AUTOSAR XML (schema 00046)
package /ComponentTypes
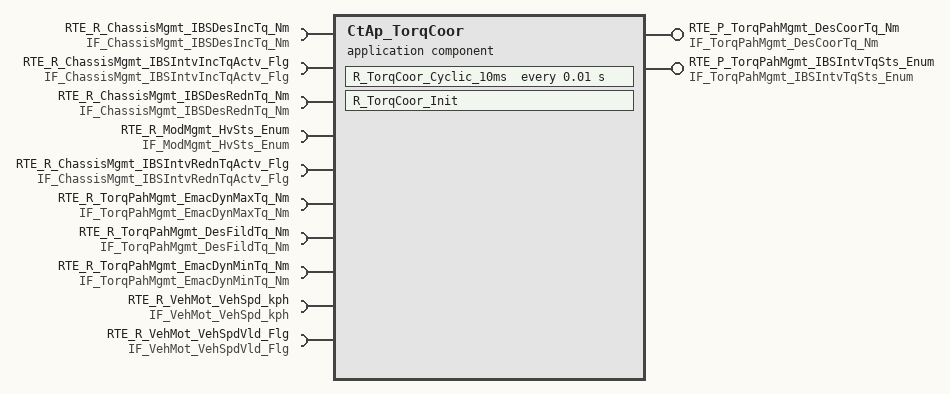
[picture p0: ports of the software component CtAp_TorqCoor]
  application sw component type CtAp_TorqCoor
    provide port RTE_P_TorqPahMgmt_DesCoorTq_Nm: nonqueued-sender-com-spec{data-element=tec_TorqPahMgmt_DesCoorTq_Nm, init-value=0}, provided-interface=IF_TorqPahMgmt_DesCoorTq_Nm
    provide port RTE_P_TorqPahMgmt_IBSIntvTqSts_Enum: nonqueued-sender-com-spec{data-element=tec_TorqPahMgmt_IBSIntvTqSts_Enum, init-value=0}, provided-interface=IF_TorqPahMgmt_IBSIntvTqSts_Enum
    10 x require port:
      RTE_R_ChassisMgmt_IBSDesIncTq_Nm: nonqueued-receiver-com-spec{data-element=tec_ChassisMgmt_IBSDesIncTq_Nm, filter=data-filter-type=ALWAYS, init-value=0}, required-interface=IF_ChassisMgmt_IBSDesIncTq_Nm
      RTE_R_ChassisMgmt_IBSIntvIncTqActv_Flg: nonqueued-receiver-com-spec{data-element=tec_ChassisMgmt_IBSIntvIncTqActv_Flg, filter=data-filter-type=ALWAYS, init-value=0}, required-interface=IF_ChassisMgmt_IBSIntvIncTqActv_Flg
      RTE_R_ChassisMgmt_IBSDesRednTq_Nm: nonqueued-receiver-com-spec{data-element=tec_ChassisMgmt_IBSDesRednTq_Nm, filter=data-filter-type=ALWAYS, init-value=0}, required-interface=IF_ChassisMgmt_IBSDesRednTq_Nm
      RTE_R_ModMgmt_HvSts_Enum: nonqueued-receiver-com-spec{data-element=tec_ModMgmt_HvSts_Enum, filter=data-filter-type=ALWAYS, init-value=0}, required-interface=IF_ModMgmt_HvSts_Enum
      RTE_R_ChassisMgmt_IBSIntvRednTqActv_Flg: nonqueued-receiver-com-spec{data-element=tec_ChassisMgmt_IBSIntvRednTqActv_Flg, filter=data-filter-type=ALWAYS, init-value=0}, required-interface=IF_ChassisMgmt_IBSIntvRednTqActv_Flg
      RTE_R_TorqPahMgmt_EmacDynMaxTq_Nm: nonqueued-receiver-com-spec{data-element=tec_TorqPahMgmt_EmacDynMaxTq_Nm, filter=data-filter-type=ALWAYS, init-value=0}, required-interface=IF_TorqPahMgmt_EmacDynMaxTq_Nm
      RTE_R_TorqPahMgmt_DesFildTq_Nm: nonqueued-receiver-com-spec{data-element=tec_TorqPahMgmt_DesFildTq_Nm, filter=data-filter-type=ALWAYS, init-value=0}, required-interface=IF_TorqPahMgmt_DesFildTq_Nm
      RTE_R_TorqPahMgmt_EmacDynMinTq_Nm: nonqueued-receiver-com-spec{data-element=tec_TorqPahMgmt_EmacDynMinTq_Nm, filter=data-filter-type=ALWAYS, init-value=0}, required-interface=IF_TorqPahMgmt_EmacDynMinTq_Nm
      RTE_R_VehMot_VehSpd_kph: nonqueued-receiver-com-spec{data-element=tec_VehMot_VehSpd_kph, filter=data-filter-type=ALWAYS, init-value=0}, required-interface=IF_VehMot_VehSpd_kph
      RTE_R_VehMot_VehSpdVld_Flg: nonqueued-receiver-com-spec{data-element=tec_VehMot_VehSpdVld_Flg, filter=data-filter-type=ALWAYS, init-value=0}, required-interface=IF_VehMot_VehSpdVld_Flg
    behavior CtAp_TorqCoor_InternalBehavior
      init event CtAp_TorqCoor_InitEvent: start-on-event=R_TorqCoor_Init
      timing event TMT_R_TorqCoor_Cyclic_10ms: start-on-event=R_TorqCoor_Cyclic_10ms, period=0.01
      runnable R_TorqCoor_Init
      runnable R_TorqCoor_Cyclic_10ms
        data-receive-point-by-arguments:
          10 x access:
            REC_RTE_R_ChassisMgmt_IBSDesIncTq_Nm_tec_ChassisMgmt_IBSDesIncTq_Nm: accessed-variable=RTE_R_ChassisMgmt_IBSDesIncTq_Nm.tec_ChassisMgmt_IBSDesIncTq_Nm
            REC_RTE_R_ChassisMgmt_IBSDesRednTq_Nm_tec_ChassisMgmt_IBSDesRednTq_Nm: accessed-variable=RTE_R_ChassisMgmt_IBSDesRednTq_Nm.tec_ChassisMgmt_IBSDesRednTq_Nm
            REC_RTE_R_ChassisMgmt_IBSIntvIncTqActv_Flg_tec_ChassisMgmt_IBSIntvIncTqActv_Flg: accessed-variable=RTE_R_ChassisMgmt_IBSIntvIncTqActv_Flg.tec_ChassisMgmt_IBSIntvIncTqActv_Flg
            REC_RTE_R_ChassisMgmt_IBSIntvRednTqActv_Flg_tec_ChassisMgmt_IBSIntvRednTqActv_Flg: accessed-variable=RTE_R_ChassisMgmt_IBSIntvRednTqActv_Flg.tec_ChassisMgmt_IBSIntvRednTqActv_Flg
            REC_RTE_R_ModMgmt_HvSts_Enum_tec_ModMgmt_HvSts_Enum: accessed-variable=RTE_R_ModMgmt_HvSts_Enum.tec_ModMgmt_HvSts_Enum
            REC_RTE_R_TorqPahMgmt_DesFildTq_Nm_tec_TorqPahMgmt_DesFildTq_Nm: accessed-variable=RTE_R_TorqPahMgmt_DesFildTq_Nm.tec_TorqPahMgmt_DesFildTq_Nm
            REC_RTE_R_TorqPahMgmt_EmacDynMaxTq_Nm_tec_TorqPahMgmt_EmacDynMaxTq_Nm: accessed-variable=RTE_R_TorqPahMgmt_EmacDynMaxTq_Nm.tec_TorqPahMgmt_EmacDynMaxTq_Nm
            REC_RTE_R_TorqPahMgmt_EmacDynMinTq_Nm_tec_TorqPahMgmt_EmacDynMinTq_Nm: accessed-variable=RTE_R_TorqPahMgmt_EmacDynMinTq_Nm.tec_TorqPahMgmt_EmacDynMinTq_Nm
            REC_RTE_R_VehMot_VehSpdVld_Flg_tec_VehMot_VehSpdVld_Flg: accessed-variable=RTE_R_VehMot_VehSpdVld_Flg.tec_VehMot_VehSpdVld_Flg
            REC_RTE_R_VehMot_VehSpd_kph_tec_VehMot_VehSpd_kph: accessed-variable=RTE_R_VehMot_VehSpd_kph.tec_VehMot_VehSpd_kph
        data-send-points:
          access SEND_RTE_P_TorqPahMgmt_DesCoorTq_Nm_tec_TorqPahMgmt_DesCoorTq_Nm: accessed-variable=RTE_P_TorqPahMgmt_DesCoorTq_Nm.tec_TorqPahMgmt_DesCoorTq_Nm
          access SEND_RTE_P_TorqPahMgmt_IBSIntvTqSts_Enum_tec_TorqPahMgmt_IBSIntvTqSts_Enum: accessed-variable=RTE_P_TorqPahMgmt_IBSIntvTqSts_Enum.tec_TorqPahMgmt_IBSIntvTqSts_Enum
  swc implementation CtAp_TorqCoor_Implementation: behavior=CtAp_TorqCoor_InternalBehavior
    code-descriptors:
      code Default: artifact-descriptors=autosar-engineering-object=category=SWOBJ
